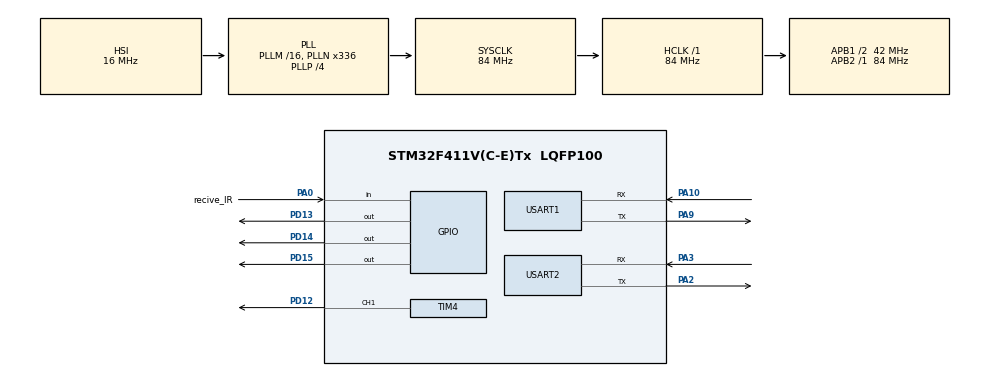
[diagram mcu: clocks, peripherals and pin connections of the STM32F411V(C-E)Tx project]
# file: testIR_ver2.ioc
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Mcu.Family=STM32F4
Mcu.Name=STM32F411V(C-E)Tx
Mcu.Package=LQFP100
NVIC.PriorityGroup=NVIC_PRIORITYGROUP_4
NVIC.TIM4_IRQn=true\:0\:0\:false\:false\:true\:true\:true
NVIC.USART1_IRQn=true\:0\:0\:false\:false\:true\:true\:true
NVIC.USART2_IRQn=true\:0\:0\:false\:false\:true\:true\:true
PA0-WKUP.GPIO_Label=recive_IR
PA0-WKUP.Signal=GPIO_Input
PA10.Mode=Asynchronous
PA10.Signal=USART1_RX
PA2.Mode=Asynchronous
PA2.Signal=USART2_TX
PA3.Mode=Asynchronous
PA3.Signal=USART2_RX
PA9.Mode=Asynchronous
PA9.Signal=USART1_TX
PD12.Signal=S_TIM4_CH1
PD13.Signal=GPIO_Output
PD14.Signal=GPIO_Output
PD15.Signal=GPIO_Output
PH0\ -\ OSC_IN.Mode=HSE-External-Oscillator
PH0\ -\ OSC_IN.Signal=RCC_OSC_IN
PH1\ -\ OSC_OUT.Mode=HSE-External-Oscillator
PH1\ -\ OSC_OUT.Signal=RCC_OSC_OUT
ProjectManager.HeapSize=0x200
ProjectManager.StackSize=0x400
ProjectManager.TargetToolchain=STM32CubeIDE
RCC.48MHZClocksFreq_Value=84000000
RCC.AHBFreq_Value=84000000
RCC.APB1CLKDivider=RCC_HCLK_DIV2
RCC.APB1Freq_Value=42000000
RCC.APB1TimFreq_Value=84000000
RCC.APB2Freq_Value=84000000
RCC.APB2TimFreq_Value=84000000
RCC.CortexFreq_Value=84000000
RCC.HCLKFreq_Value=84000000
RCC.HSE_VALUE=25000000
RCC.HSI_VALUE=16000000
RCC.LSE_VALUE=32768
RCC.PLLN=336
RCC.PLLP=RCC_PLLP_DIV4
RCC.SYSCLKFreq_VALUE=84000000
RCC.SYSCLKSource=RCC_SYSCLKSOURCE_PLLCLK
RCC.VCOOutputFreq_Value=336000000
SH.S_TIM4_CH1.0=TIM4_CH1,PWM Generation1 CH1
TIM4.Channel-PWM\ Generation1\ CH1=TIM_CHANNEL_1
USART1.VirtualMode=VM_ASYNC
USART2.VirtualMode=VM_ASYNC
VP_TIM4_VS_ClockSourceINT.Mode=Internal
board=custom

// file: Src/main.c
/* USER CODE BEGIN Header */
/**
  ******************************************************************************
  * @file           : main.c
  * @brief          : Main program body
  ******************************************************************************
  * @attention
  *
  * <h2><center>&copy; Copyright (c) 2020 STMicroelectronics.
  * All rights reserved.</center></h2>
  *
  * This software component is licensed by ST under BSD 3-Clause license,
  * the "License"; You may not use this file except in compliance with the
  * License. You may obtain a copy of the License at:
  *                        opensource.org/licenses/BSD-3-Clause
  *
  ******************************************************************************
  */
/* USER CODE END Header */

#include "main.h"

#include "string.h"
#include "IRremote.h"

TIM_HandleTypeDef htim4;

UART_HandleTypeDef huart1;
UART_HandleTypeDef huart2;

void SystemClock_Config(void);
static void MX_GPIO_Init(void);
static void MX_TIM4_Init(void);
static void MX_USART1_UART_Init(void);
static void MX_USART2_UART_Init(void);

int main(void)
{

  /* MCU Configuration--------------------------------------------------------*/

  /* Reset of all peripherals, Initializes the Flash interface and the Systick. */
  HAL_Init();

  /* Configure the system clock */
  SystemClock_Config();

  /* Initialize all configured peripherals */
  MX_GPIO_Init();
  MX_TIM4_Init();
  MX_USART1_UART_Init();
  MX_USART2_UART_Init();
  /* USER CODE BEGIN 2 */
  char trans_str[96] = {0,};
  snprintf(trans_str, 64, "IR-rec-trans https://istarik.ru/blog/stm32/125.html\n");
  HAL_UART_Transmit(&huart1, (uint8_t*)trans_str, strlen(trans_str), 100);
  //my_enableIRIn(); 
  /* USER CODE END 2 */
  my_enableIRIn();

  /* Infinite loop */
  /* USER CODE BEGIN WHILE */
  static char *decode_str[] = {"UNUSED", "UNKNOWN", "RC5", "RC6", "NEC", "SONY", "PANASONIC", "JVC", "SAMSUNG", "WHYNTER", "AIWA_RC_T501", "LG", "SANYO", "MITSUBISHI", "DISH", "SHARP", "DENON", "PRONTO"};
  while (1)
  {
    /* USER CODE END WHILE */
		if(my_decode(&results))
		{

			//snprintf(trans_str, 96, "Cod: %p | Type: %s | Bits: %d\n", (void*)results.value, decode_str[results.decode_type + 1], results.bits);
			sprintf(trans_str,"Cod: %p | Type: %s | Bits: %d\n", (void*)results.value, decode_str[results.decode_type + 1], results.bits);
			HAL_UART_Transmit(&huart1, (uint8_t*)&trans_str, strlen(trans_str), 100);
			HAL_Delay(300);
			my_resume();
		}
		HAL_UART_Transmit(&huart1, (char*)&trans_str, strlen(trans_str), 100);
		HAL_Delay(1000);

  }
}

void SystemClock_Config(void)
{
  RCC_OscInitTypeDef RCC_OscInitStruct = {0};
  RCC_ClkInitTypeDef RCC_ClkInitStruct = {0};

  /** Configure the main internal regulator output voltage
  */
  __HAL_RCC_PWR_CLK_ENABLE();
  __HAL_PWR_VOLTAGESCALING_CONFIG(PWR_REGULATOR_VOLTAGE_SCALE1);
  /** Initializes the CPU, AHB and APB busses clocks
  */
  RCC_OscInitStruct.OscillatorType = RCC_OSCILLATORTYPE_HSI;
  RCC_OscInitStruct.HSIState = RCC_HSI_ON;
  RCC_OscInitStruct.HSICalibrationValue = RCC_HSICALIBRATION_DEFAULT;
  RCC_OscInitStruct.PLL.PLLState = RCC_PLL_ON;
  RCC_OscInitStruct.PLL.PLLSource = RCC_PLLSOURCE_HSI;
  RCC_OscInitStruct.PLL.PLLM = 16;
  RCC_OscInitStruct.PLL.PLLN = 336;
  RCC_OscInitStruct.PLL.PLLP = RCC_PLLP_DIV4;
  RCC_OscInitStruct.PLL.PLLQ = 4;
  if (HAL_RCC_OscConfig(&RCC_OscInitStruct) != HAL_OK)
  {
    Error_Handler();
  }
  /** Initializes the CPU, AHB and APB busses clocks
  */
  RCC_ClkInitStruct.ClockType = RCC_CLOCKTYPE_HCLK|RCC_CLOCKTYPE_SYSCLK
                              |RCC_CLOCKTYPE_PCLK1|RCC_CLOCKTYPE_PCLK2;
  RCC_ClkInitStruct.SYSCLKSource = RCC_SYSCLKSOURCE_PLLCLK;
  RCC_ClkInitStruct.AHBCLKDivider = RCC_SYSCLK_DIV1;
  RCC_ClkInitStruct.APB1CLKDivider = RCC_HCLK_DIV2;
  RCC_ClkInitStruct.APB2CLKDivider = RCC_HCLK_DIV1;

  if (HAL_RCC_ClockConfig(&RCC_ClkInitStruct, FLASH_LATENCY_2) != HAL_OK)
  {
    Error_Handler();
  }
}

static void MX_TIM4_Init(void)
{

  TIM_ClockConfigTypeDef sClockSourceConfig = {0};
  TIM_MasterConfigTypeDef sMasterConfig = {0};
  TIM_OC_InitTypeDef sConfigOC = {0};

  htim4.Instance = TIM4;
  htim4.Init.Prescaler = 0;
  htim4.Init.CounterMode = TIM_COUNTERMODE_UP;
  htim4.Init.Period = 0;
  htim4.Init.ClockDivision = TIM_CLOCKDIVISION_DIV1;
  htim4.Init.AutoReloadPreload = TIM_AUTORELOAD_PRELOAD_DISABLE;
  if (HAL_TIM_Base_Init(&htim4) != HAL_OK)
  {
    Error_Handler();
  }
  sClockSourceConfig.ClockSource = TIM_CLOCKSOURCE_INTERNAL;
  if (HAL_TIM_ConfigClockSource(&htim4, &sClockSourceConfig) != HAL_OK)
  {
    Error_Handler();
  }
  if (HAL_TIM_PWM_Init(&htim4) != HAL_OK)
  {
    Error_Handler();
  }
  sMasterConfig.MasterOutputTrigger = TIM_TRGO_RESET;
  sMasterConfig.MasterSlaveMode = TIM_MASTERSLAVEMODE_DISABLE;
  if (HAL_TIMEx_MasterConfigSynchronization(&htim4, &sMasterConfig) != HAL_OK)
  {
    Error_Handler();
  }
  sConfigOC.OCMode = TIM_OCMODE_PWM1;
  sConfigOC.Pulse = 0;
  sConfigOC.OCPolarity = TIM_OCPOLARITY_HIGH;
  sConfigOC.OCFastMode = TIM_OCFAST_DISABLE;
  if (HAL_TIM_PWM_ConfigChannel(&htim4, &sConfigOC, TIM_CHANNEL_1) != HAL_OK)
  {
    Error_Handler();
  }
  HAL_TIM_MspPostInit(&htim4);

}

static void MX_USART1_UART_Init(void)
{

  huart1.Instance = USART1;
  huart1.Init.BaudRate = 115200;
  huart1.Init.WordLength = UART_WORDLENGTH_8B;
  huart1.Init.StopBits = UART_STOPBITS_1;
  huart1.Init.Parity = UART_PARITY_NONE;
  huart1.Init.Mode = UART_MODE_TX_RX;
  huart1.Init.HwFlowCtl = UART_HWCONTROL_NONE;
  huart1.Init.OverSampling = UART_OVERSAMPLING_16;
  if (HAL_UART_Init(&huart1) != HAL_OK)
  {
    Error_Handler();
  }

}

static void MX_USART2_UART_Init(void)
{

  huart2.Instance = USART2;
  huart2.Init.BaudRate = 115200;
  huart2.Init.WordLength = UART_WORDLENGTH_8B;
  huart2.Init.StopBits = UART_STOPBITS_1;
  huart2.Init.Parity = UART_PARITY_NONE;
  huart2.Init.Mode = UART_MODE_TX_RX;
  huart2.Init.HwFlowCtl = UART_HWCONTROL_NONE;
  huart2.Init.OverSampling = UART_OVERSAMPLING_16;
  if (HAL_UART_Init(&huart2) != HAL_OK)
  {
    Error_Handler();
  }

}

static void MX_GPIO_Init(void)
{
  GPIO_InitTypeDef GPIO_InitStruct = {0};

  /* GPIO Ports Clock Enable */
  __HAL_RCC_GPIOH_CLK_ENABLE();
  __HAL_RCC_GPIOA_CLK_ENABLE();
  __HAL_RCC_GPIOD_CLK_ENABLE();

  /*Configure GPIO pin Output Level */
  HAL_GPIO_WritePin(GPIOD, GPIO_PIN_13|GPIO_PIN_14|GPIO_PIN_15, GPIO_PIN_RESET);

  /*Configure GPIO pin : recive_IR_Pin */
  GPIO_InitStruct.Pin = recive_IR_Pin;
  GPIO_InitStruct.Mode = GPIO_MODE_INPUT;
  GPIO_InitStruct.Pull = GPIO_NOPULL;
  HAL_GPIO_Init(recive_IR_GPIO_Port, &GPIO_InitStruct);

  /*Configure GPIO pins : PD13 PD14 PD15 */
  GPIO_InitStruct.Pin = GPIO_PIN_13|GPIO_PIN_14|GPIO_PIN_15;
  GPIO_InitStruct.Mode = GPIO_MODE_OUTPUT_PP;
  GPIO_InitStruct.Pull = GPIO_NOPULL;
  GPIO_InitStruct.Speed = GPIO_SPEED_FREQ_LOW;
  HAL_GPIO_Init(GPIOD, &GPIO_InitStruct);

}

void Error_Handler(void)
{
}

/************************ (C) COPYRIGHT STMicroelectronics *****END OF FILE****/
